# PY32MD320xx register map
Vendor: Puya; Series: PY32M; File version: 1.0.0
CPU: CM0+ r0p1, little endian, no MPU, no FPU, 4 interrupt priority bits
Registers are 32-bit, read-write, reset 0x0 unless marked. A register's access mark holds for its fields unless they carry their own. Offsets are from the block's base; [hi:lo] are bit positions; {n}, {i} and the like mark numbered series.

## SPI1 — Serial peripheral interface
Base 0x40013000
Same registers: SPI2 0x40003800
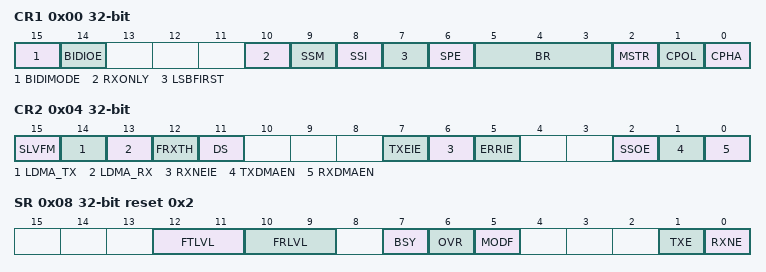
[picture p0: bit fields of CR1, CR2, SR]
0x00 CR1 — control register 1
  [15] BIDIMODE — Bidirectional data mode enable
  [14] BIDIOE — Output enable in bidirectional mode
  [10] RXONLY — Receive only
  [9] SSM — Software slave management
  [8] SSI — Internal slave selection
  [7] LSBFIRST — Frame format
  [6] SPE — SPI enable
  [5:3] BR — Baud rate control
    1=0; 2=1; 4=2
  [2] MSTR — Master selection
  [1] CPOL — Clock polarity
  [0] CPHA — Clock phase
0x04 CR2 — control register 2
  [15] SLVFM — Slave fast mode enable
  [14] LDMA_TX — Last DAM Transmit(TX)
  [13] LDMA_RX — Last DAM Transmit(RX)
  [12] FRXTH — FIFO reception threshold
  [11] DS — Data length
  [7] TXEIE — Tx buffer empty interrupt enable
  [6] RXNEIE — RX buffer not empty interrupt enable
  [5] ERRIE — Error interrupt enable
  [2] SSOE — SS output enable
  [1] TXDMAEN — Tx buffer DMA enable
  [0] RXDMAEN — Rx buffer DMA enable
0x08 SR reset 0x2 — status register
  [12:11] FTLVL ro — FIFO transmission level
    1=0; 2=1
  [10:9] FRLVL ro — FIFO reception level
    1=0; 2=1
  [7] BSY ro — Busy flag
  [6] OVR ro — Overrun flag
  [5] MODF ro — Mode fault
  [1] TXE ro — Transmit buffer empty
  [0] RXNE ro — Receive buffer not empty
0x0C DR — data register
  [15:0] DR — Data register

## SYSCFG — System configuration controller
Base 0x40010000
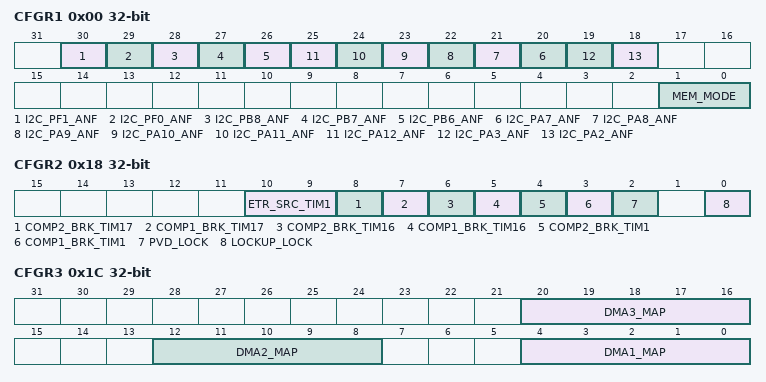
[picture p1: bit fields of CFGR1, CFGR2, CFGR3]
0x00 CFGR1 — SYSCFG configuration register1
  [30] I2C_PF1_ANF — Analog filter enable control driving capabilityactivation bits PF1
  [29] I2C_PF0_ANF — Analog filter enable control driving capabilityactivation bits PF0
  [28] I2C_PB8_ANF — Analog filter enable control driving capabilityactivation bits PB8
  [27] I2C_PB7_ANF — Analog filter enable control driving capabilityactivation bits PB7
  [26] I2C_PB6_ANF — Analog filter enable control driving capabilityactivation bits PB6
  [n+13] I2C_PA{n}_ANF (n=7..12) — Analog filter enable control driving capabilityactivation bits PA{n}
  [19] I2C_PA3_ANF — Analog filter enable control driving capabilityactivation bits PA3
  [18] I2C_PA2_ANF — Analog filter enable control driving capabilityactivation bits PA2
  [1:0] MEM_MODE — Memory mapping selectionbits
    1=0; 2=1
0x18 CFGR2 — SYSCFG configuration register2
  [10:9] ETR_SRC_TIM1 — TIM1 ETR source selection
    1=0; 2=1
  [8] COMP2_BRK_TIM17 — COMP2 is enable to input of TIM17 break
  [7] COMP1_BRK_TIM17 — COMP1 is enable to input of TIM17 break
  [6] COMP2_BRK_TIM16 — COMP2 is enable to input of TIM16 break
  [5] COMP1_BRK_TIM16 — COMP1 is enable to input of TIM16 break
  [4] COMP2_BRK_TIM1 — COMP2 is enable to input of TIM1 break
  [3] COMP1_BRK_TIM1 — COMP1 is enable to input of TIM1 break
  [2] PVD_LOCK — PVD lock enable bit
  [0] LOCKUP_LOCK — Cortex-M0+ LOCKUP bit enablebit
0x1C CFGR3 — SYSCFG configuration register3
  [all] fields
    1=0; 2=1; 4=2; 8=3; 16=4
  [20:16] DMA3_MAP — DMA channel3 requeset selection
  [12:8] DMA2_MAP — DMA channel2 requeset selection
  [4:0] DMA1_MAP — DMA channel1 requeset selection

## TIM14 — General purpose timer
Base 0x40002000
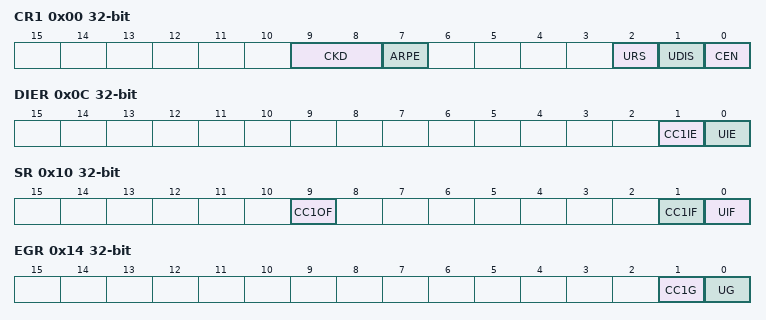
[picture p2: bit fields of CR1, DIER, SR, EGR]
0x00 CR1 — TIM14 control register1
  [9:8] CKD — Prescaler factor
    1=0; 2=1
  [7] ARPE — Auto-reload preload enable
  [2] URS — Update request source
  [1] UDIS — Update disable
  [0] CEN — Counter enable
0x0C DIER — DMA/Interrupt enable register
  [1] CC1IE — Compare/
  [0] UIE — Update interrupt enable
0x10 SR — status register
  [9] CC1OF — Compare/capture 1 flag
  [1] CC1IF — Compare/capture 1 interrupt flag
  [0] UIF — Update interrupt flag
0x14 EGR wo — event generation register
  [1] CC1G — Compare/capture1 event
  [0] UG — Update generation
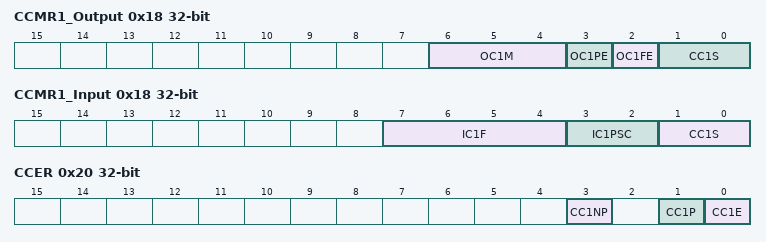
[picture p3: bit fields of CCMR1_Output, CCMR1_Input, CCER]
0x18 CCMR1_Output — capture/compare mode register (outputmode)
  [6:4] OC1M — Output Compare 1 mode
  [3] OC1PE — Output Compare 1 preloadenable
  [2] OC1FE — Output Compare 1 fastenable
  [1:0] CC1S — Capture/Compare 1selection
0x18 CCMR1_Input (alternate view of CCMR1_Output) — capture/compare mode register 1 (inputmode)
  [7:4] IC1F — Input capture 1 filter
  [3:2] IC1PSC — Input capture 1 prescaler
  [1:0] CC1S — Capture/Compare 1selection
0x20 CCER — capture/compare enableregister
  [3] CC1NP — Capture/Compare 1 outputPolarity
  [1] CC1P — Capture/Compare 1 outputPolarity
  [0] CC1E — Capture/Compare 1 outputenable
0x24 CNT — counter
  [15:0] CNT — counter value
0x28 PSC — prescaler
  [15:0] PSC — Prescaler value
0x2C ARR — auto-reload register
  [15:0] ARR — Auto-reload value
0x34 CCR1 — capture/compare register 1
  [15:0] CCR1 — Capture/Compare 1 value
0x50 OR — Option register
  [1:0] TI1_RMP — TIM14 channel1 input remap
    1=0; 2=1
